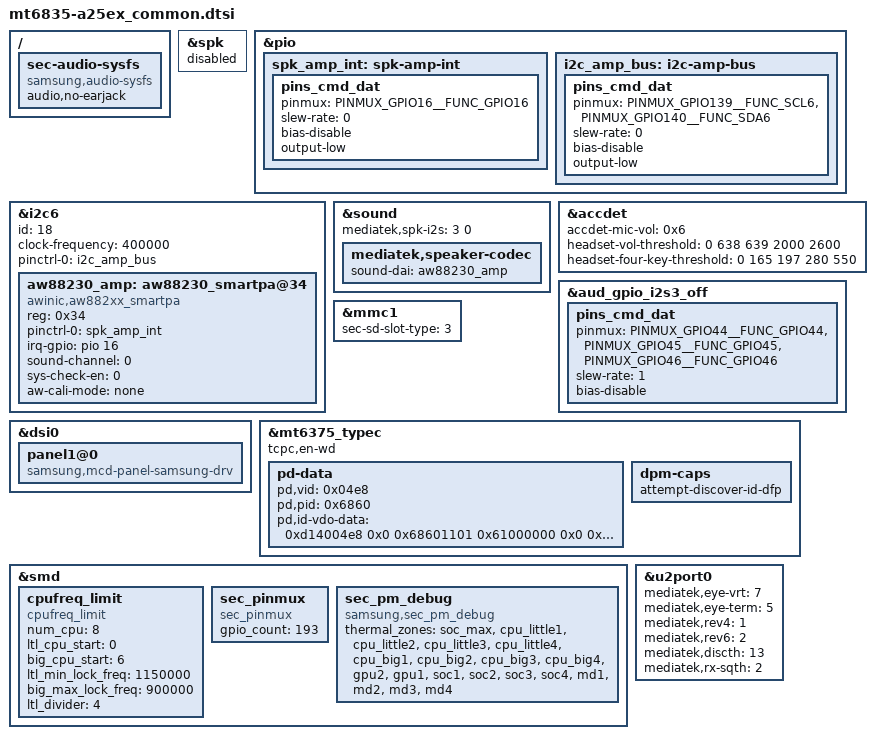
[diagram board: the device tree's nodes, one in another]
/* Generated by Samsung for MTK vendor board
 * If these files should be changed, then please make a sync with MTK
*/

/* Add Samsung configuration over here */

/ {
	fragment@model {
		target-path = "/";
		__overlay__ {
			sec-audio-sysfs {
				compatible = "samsung,audio-sysfs";
				status = "okay";
				audio,no-earjack;
				/* audio,num-amp = <1>; */
			};
		};
	};
};

&spk {
	status = "disabled";
};

&pio {
	spk_amp_int: spk-amp-int {
		pins_cmd_dat {
			pinmux = <PINMUX_GPIO16__FUNC_GPIO16>;
			slew-rate = <0>;
			bias-disable;
			output-low;
		};
	};

	/* need to check power down timing */
	i2c_amp_bus: i2c-amp-bus {
		pins_cmd_dat {
			pinmux = <PINMUX_GPIO139__FUNC_SCL6>,
				<PINMUX_GPIO140__FUNC_SDA6>;
			slew-rate = <0>;
			bias-disable;
			output-low;
		};
	};
};

&i2c6 {
	#address-cells = <1>;
	#size-cells = <0>;
	status = "okay";
	id = <18>;
	clock-frequency = <400000>;

	pinctrl-names = "default";
	pinctrl-0 = <&i2c_amp_bus>;

	aw88230_amp: aw88230_smartpa@34 {
		compatible = "awinic,aw882xx_smartpa";
		#sound-dai-cells = <0>;
		reg = <0x34>;

		pinctrl-names = "default";
		pinctrl-0 = <&spk_amp_int>;

		irq-gpio = <&pio 16 0>;

		sound-channel = <0>;
		sys-check-en = <0>;
		aw-cali-mode = "none";
		status = "okay";
	};
};

&sound {
	mediatek,spk-i2s = <3 0>;
	mediatek,speaker-codec {
		sound-dai = <&aw88230_amp>;
	};
};

&accdet {
	accdet-mic-vol = <0x6>;
	/* min_3pole--max_3pole--min_4pole--max_4pole--vol_bias */
	headset-vol-threshold = <0 638 639 2000 2600>;
	/* 0--MD_MAX--VOICE_MAX--UP_MAX--DW_MAX */
	headset-four-key-threshold = <0 165 197 280 550>;
};

&aud_gpio_i2s3_off {
	pins_cmd_dat {
		pinmux = <PINMUX_GPIO44__FUNC_GPIO44>,
			 <PINMUX_GPIO45__FUNC_GPIO45>,
			 <PINMUX_GPIO46__FUNC_GPIO46>;
		slew-rate = <1>;
		bias-disable;
	};
};

&mmc1 {
	sec-sd-slot-type = <3>; /* Hybrid Tray SD slot */
};

&dsi0 {
	panel1@0 {
		compatible = "samsung,mcd-panel-samsung-drv";
	};
};

&mt6375_typec {
	tcpc,en-wd;
	pd-data {
		pd,vid = <0x04e8>;
		pd,pid = <0x6860>;
				/* Discover Identity Command response
				 * from 6.4.4.3.1 in PD rev 3.1 ver 1.8
				 */
		pd,id-vdo-data = <0xd14004e8 0x0 0x68601101 /* ID Header VDO / Cert Stat VDO / Product VDO */
				 0x61000000 0x0 0x41000000>; /* Product Type VDOs (UFP / Pad / DFP) */
	};

	dpm-caps {
		attempt-discover-id-dfp;
	};
};

&smd {
	cpufreq_limit {
		status = "okay";
		compatible = "cpufreq_limit";

		num_cpu = <8>;
		ltl_cpu_start = <0>;
		big_cpu_start = <6>;
		ltl_min_lock_freq = <1150000>;
		big_max_lock_freq = <900000>;
		ltl_divider = <4>;
	};

	sec_pinmux {
		status = "okay";
		compatible = "sec_pinmux";

		gpio_count = <193>;
	};

	sec_pm_debug {
		status = "okay";
		compatible = "samsung,sec_pm_debug";

		thermal_zones = "soc_max",
						"cpu_little1", "cpu_little2",
						"cpu_little3", "cpu_little4",
						"cpu_big1", "cpu_big2",
						"cpu_big3", "cpu_big4",
						"gpu2", "gpu1", "soc1", "soc2", "soc3", "soc4",
						"md1", "md2", "md3", "md4";
	};
};

&u2port0 {
	mediatek,eye-vrt = <7>;
	mediatek,eye-term = <5>;
	mediatek,rev4 = <1>;
	mediatek,rev6 = <2>;
	mediatek,discth = <13>;
	mediatek,rx-sqth = <2>;
};
